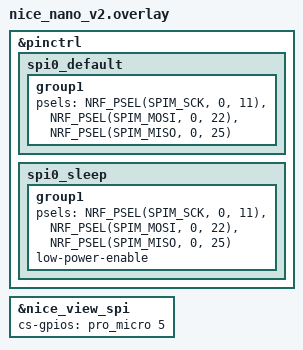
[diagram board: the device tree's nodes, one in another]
&pinctrl {
    spi0_default: spi0_default {
        group1 {
            psels = <NRF_PSEL(SPIM_SCK, 0, 11)>,
                <NRF_PSEL(SPIM_MOSI, 0, 22)>,
                <NRF_PSEL(SPIM_MISO, 0, 25)>;
        };
    };
    spi0_sleep: spi0_sleep {
        group1 {
            psels = <NRF_PSEL(SPIM_SCK, 0, 11)>,
                <NRF_PSEL(SPIM_MOSI, 0, 22)>,
                <NRF_PSEL(SPIM_MISO, 0, 25)>;
            low-power-enable;
        };
    };
};

&nice_view_spi {
    cs-gpios = <&pro_micro 5 GPIO_ACTIVE_HIGH>;
};
